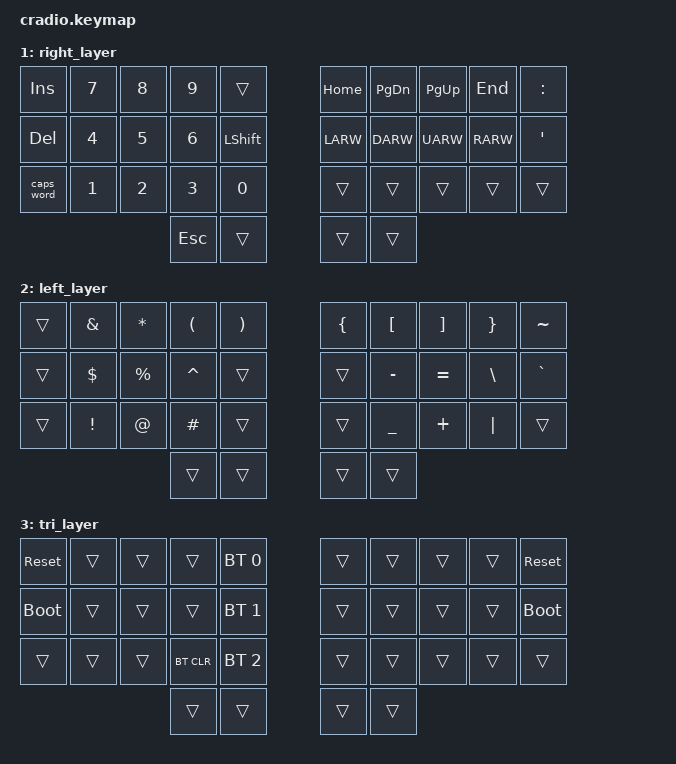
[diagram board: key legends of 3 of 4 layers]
// Copyright (c) 2022 The ZMK Contributors
// SPDX-License-Identifier: MIT

#include <behaviors.dtsi>
#include <dt-bindings/zmk/keys.h>
#include <dt-bindings/zmk/bt.h>

// Home row mods macro
#define HRML(k1,k2,k3,k4) &ht LGUI k1  &ht LALT k2  &ht LCTRL k3  &ht LSHFT k4
#define HRMR(k1,k2,k3,k4) &ht RSHFT k1  &ht RCTRL k2  &ht RALT k3  &ht RGUI k4

/ {
    behaviors {
        ht: hold_tap {
            label = "hold_tap";
            compatible = "zmk,behavior-hold-tap";
            #binding-cells = <2>;
            flavor = "tap-preferred";
            tapping-term-ms = <220>;
            quick-tap-ms = <150>;
            global-quick-tap;
            bindings = <&kp>, <&kp>;
        };
    };

    conditional_layers {
        compatible = "zmk,conditional-layers";
        tri_layer {
            if-layers = <1 2>;
            then-layer = <3>;
        };
    };

    keymap {
        compatible = "zmk,keymap";
        default_layer {
            bindings = <
        //╭──────────┬──────────┬──────────┬──────────┬──────────╮   ╭──────────┬──────────┬──────────┬──────────┬──────────╮
        //│  Q       │  W       │   F      │  P       │  G       │   │  J       │  L       │  U       │  Y       │  ;       │
            &kp Q      &kp W      &kp F      &kp P      &kp G          &kp J      &kp L      &kp U      &kp Y      &kp SEMI
        //├──────────┼──────────┼──────────┼──────────┼──────────┤   ├──────────┼──────────┼──────────┼──────────┼──────────┤
        //│  A       │  R       │  S       │  T       │  D       │   │  H       │  N       │  E       │  I       │ O        │
            HRML(A,        R,         S,         T)     &kp D          &kp H      HRMR(N,        E,         I,        O)
        //├──────────┼──────────┼──────────┼──────────┼──────────┤   ├──────────┼──────────┼──────────┼──────────┼──────────┤
        //│  Z       │  X       │  C       │  V       │  B       │   │  K       │  M       │  , <     │   . >    │ / ?      │
            &kp Z      &kp X      &kp C      &kp V      &kp B          &kp K      &kp M      &kp COMMA  &kp DOT    &kp FSLH
        //╰──────────┴──────────┴──────────┼──────────┼──────────┤   ├──────────┼──────────┼──────────┴──────────┴──────────╯
                                            &kp TAB   &lt 2 SPACE     &lt 1 BSPC   &kp ENTER 
        //                                 ╰──────────┴──────────╯   ╰──────────┴──────────╯
            >;
        };

        right_layer {
            bindings = <
        //╭──────────┬──────────┬──────────┬──────────┬──────────╮   ╭──────────┬──────────┬──────────┬──────────┬──────────╮
        //│ INSERT   │  7       │  8       │  9       │          │   │ HOME     │ PAGE DN  │ PAGE UP  │ END      │  :       │
            &kp INS    &kp N7     &kp N8     &kp N9     &trans         &kp HOME   &kp PG_DN  &kp PG_UP  &kp END    &kp COLON
        //├──────────┼──────────┼──────────┼──────────┼──────────┤   ├──────────┼──────────┼──────────┼──────────┼──────────┤
        //│ DELETE   │  4       │  5       │  6       │          │   │ LEFT     │ DOWN     │ UP       │ RIGHT    │  ' "     │
            &kp DEL    &kp N4     &kp N5     &kp N6     &kp LSHFT         &kp LARW   &kp DARW   &kp UARW   &kp RARW   &kp SINGLE_QUOTE
        //├──────────┼──────────┼──────────┼──────────┼──────────┤   ├──────────┼──────────┼──────────┼──────────┼──────────┤
        //│ CAPS     │  1       │  2       │  3       │  0       │   │          │          │          │          │          │
           &caps_word  &kp N1     &kp N2     &kp N3     &kp N0         &trans     &trans     &trans     &trans     &trans
        //╰──────────┴──────────┴──────────┼──────────┼──────────┤   ├──────────┼──────────┼──────────┴──────────┴──────────╯
                                             &kp ESC     &trans        &trans     &trans
        //                                 ╰──────────┴──────────╯   ╰──────────┴──────────╯
            >;
        };

        left_layer {
            bindings = <
        //╭──────────┬──────────┬──────────┬──────────┬──────────╮   ╭──────────┬──────────┬──────────┬──────────┬──────────╮
        //│          │  &       │  *       │  (       │    )     │   │       {  │    [     │     ]    │  }       │  ~       │
            &trans     &kp AMPS   &kp STAR   &kp LPAR   &kp RPAR      &kp LBRC  &kp LBKT   &kp RBKT   &kp RBRC   &kp TILDE
        //├──────────┼──────────┼──────────┼──────────┼──────────┤   ├──────────┼──────────┼──────────┼──────────┼──────────┤
        //│          │  $       │  %       │  ^       │          │   │          │  -       │  =       │  \       │  `       │
            &trans    &kp DLLR   &kp PRCNT  &kp CARET   &trans          &trans  &kp MINUS  &kp EQUAL  &kp BSLH   &kp GRAVE
        //├──────────┼──────────┼──────────┼──────────┼──────────┤   ├──────────┼──────────┼──────────┼──────────┼──────────┤
        //│          │   !      │      @   │   #      │          │   │          │  _       │  +       │  │       │          │
            &trans     &kp EXCL    &kp AT    &kp HASH   &trans         &trans   &kp UNDER  &kp PLUS   &kp PIPE    &trans
        //╰──────────┴──────────┴──────────┼──────────┼──────────┤   ├──────────┼──────────┼──────────┴──────────┴──────────╯
                                             &trans     &trans         &trans     &trans
        //                                 ╰──────────┴──────────╯   ╰──────────┴──────────╯
            >;
        };

        tri_layer {
            bindings = <
        //╭──────────┬──────────┬──────────┬──────────┬──────────╮   ╭──────────┬──────────┬──────────┬──────────┬──────────╮
        //│ RESET    │          │          │          │PROFILE 0 │   │          │          │          │          │  RESET   │
           &sys_reset  &trans     &trans     &trans    &bt BT_SEL 0    &trans     &trans     &trans     &trans    &sys_reset
        //├──────────┼──────────┼──────────┼──────────┼──────────┤   ├──────────┼──────────┼──────────┼──────────┼──────────┤
        //│BOOTLOADER│          │          │          │PROFILE 1 │   │          │          │          │          │BOOTLOADER│
          &bootloader  &trans     &trans     &trans    &bt BT_SEL 1    &trans     &trans     &trans     &trans    &bootloader
        //├──────────┼──────────┼──────────┼──────────┼──────────┤   ├──────────┼──────────┼──────────┼──────────┼──────────┤
        //│          │          │          │ CLEAR BT │PROFILE 2 │   │          │          │          │          │          │
            &trans     &trans     &trans    &bt BT_CLR &bt BT_SEL 2    &trans     &trans     &trans     &trans     &trans
        //╰──────────┴──────────┴──────────┼──────────┼──────────┤   ├──────────┼──────────┼──────────┴──────────┴──────────╯
                                             &trans     &trans         &trans     &trans
        //                                 ╰──────────┴──────────╯   ╰──────────┴──────────╯
            >;
        };
    };
};
